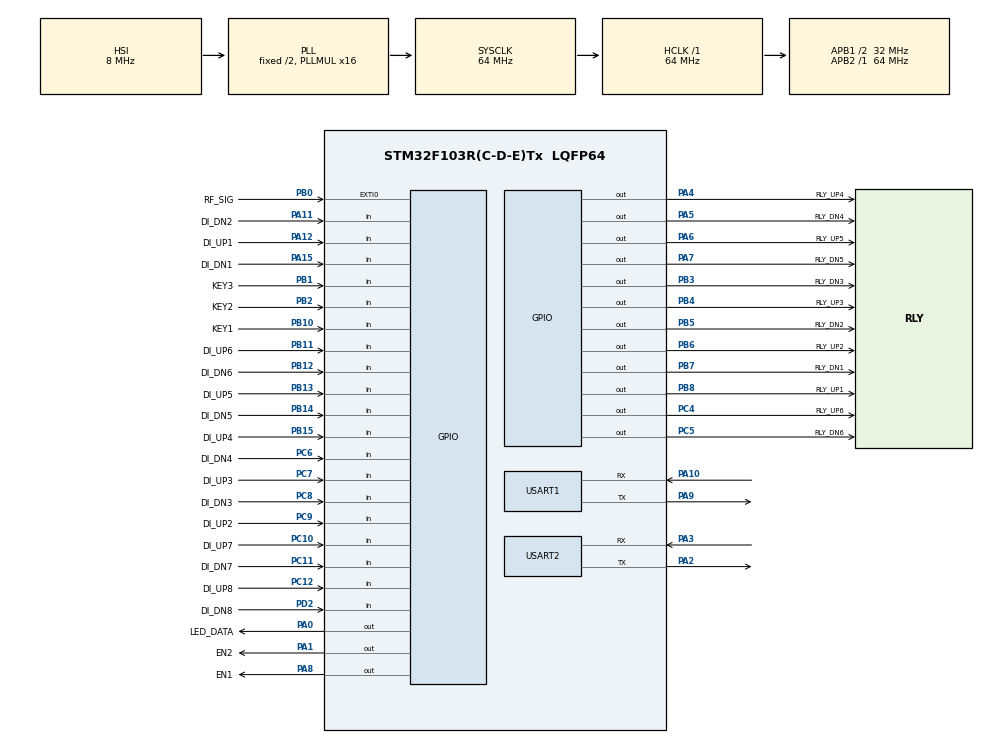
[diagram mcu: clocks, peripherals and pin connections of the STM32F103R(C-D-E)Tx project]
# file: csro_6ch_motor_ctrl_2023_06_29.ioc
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Dma.Request0=USART1_RX
Dma.Request1=USART1_TX
Dma.Request2=USART2_RX
Dma.Request3=USART2_TX
Dma.Request4=TIM2_UP
Dma.TIM2_UP.4.Direction=DMA_MEMORY_TO_PERIPH
Dma.TIM2_UP.4.Instance=DMA1_Channel2
Dma.TIM2_UP.4.MemDataAlignment=DMA_MDATAALIGN_WORD
Dma.TIM2_UP.4.MemInc=DMA_MINC_ENABLE
Dma.TIM2_UP.4.Mode=DMA_NORMAL
Dma.TIM2_UP.4.PeriphDataAlignment=DMA_PDATAALIGN_WORD
Dma.TIM2_UP.4.PeriphInc=DMA_PINC_DISABLE
Dma.TIM2_UP.4.Priority=DMA_PRIORITY_LOW
Dma.USART1_RX.0.Direction=DMA_PERIPH_TO_MEMORY
Dma.USART1_RX.0.Instance=DMA1_Channel5
Dma.USART1_RX.0.MemDataAlignment=DMA_MDATAALIGN_BYTE
Dma.USART1_RX.0.MemInc=DMA_MINC_ENABLE
Dma.USART1_RX.0.Mode=DMA_CIRCULAR
Dma.USART1_RX.0.PeriphDataAlignment=DMA_PDATAALIGN_BYTE
Dma.USART1_RX.0.PeriphInc=DMA_PINC_DISABLE
Dma.USART1_RX.0.Priority=DMA_PRIORITY_LOW
Dma.USART1_TX.1.Direction=DMA_MEMORY_TO_PERIPH
Dma.USART1_TX.1.Instance=DMA1_Channel4
Dma.USART1_TX.1.MemDataAlignment=DMA_MDATAALIGN_BYTE
Dma.USART1_TX.1.MemInc=DMA_MINC_ENABLE
Dma.USART1_TX.1.Mode=DMA_NORMAL
Dma.USART1_TX.1.PeriphDataAlignment=DMA_PDATAALIGN_BYTE
Dma.USART1_TX.1.PeriphInc=DMA_PINC_DISABLE
Dma.USART1_TX.1.Priority=DMA_PRIORITY_LOW
Dma.USART2_RX.2.Direction=DMA_PERIPH_TO_MEMORY
Dma.USART2_RX.2.Instance=DMA1_Channel6
Dma.USART2_RX.2.MemDataAlignment=DMA_MDATAALIGN_BYTE
Dma.USART2_RX.2.MemInc=DMA_MINC_ENABLE
Dma.USART2_RX.2.Mode=DMA_CIRCULAR
Dma.USART2_RX.2.PeriphDataAlignment=DMA_PDATAALIGN_BYTE
Dma.USART2_RX.2.PeriphInc=DMA_PINC_DISABLE
Dma.USART2_RX.2.Priority=DMA_PRIORITY_LOW
Dma.USART2_TX.3.Direction=DMA_MEMORY_TO_PERIPH
Dma.USART2_TX.3.Instance=DMA1_Channel7
Dma.USART2_TX.3.MemDataAlignment=DMA_MDATAALIGN_BYTE
Dma.USART2_TX.3.MemInc=DMA_MINC_ENABLE
Dma.USART2_TX.3.Mode=DMA_NORMAL
Dma.USART2_TX.3.PeriphDataAlignment=DMA_PDATAALIGN_BYTE
Dma.USART2_TX.3.PeriphInc=DMA_PINC_DISABLE
Dma.USART2_TX.3.Priority=DMA_PRIORITY_LOW
FREERTOS.Tasks01=Task01,47,128,StartTask01,Default,NULL,Dynamic,NULL,NULL;Task02,45,128,StartTask02,Default,NULL,Dynamic,NULL,NULL;Task03,43,128,StartTask03,Default,NULL,Dynamic,NULL,NULL;Task04,41,128,StartTask04,Default,NULL,Dynamic,NULL,NULL;Task05,24,128,StartTask05,Default,NULL,Dynamic,NULL,NULL
FREERTOS.configTOTAL_HEAP_SIZE=4096
FREERTOS.configUSE_NEWLIB_REENTRANT=1
Mcu.Family=STM32F1
Mcu.Name=STM32F103R(C-D-E)Tx
Mcu.Package=LQFP64
NVIC.DMA1_Channel2_IRQn=true\:5\:0\:false\:false\:true\:true\:false\:true\:true
NVIC.DMA1_Channel4_IRQn=true\:5\:0\:false\:false\:true\:true\:false\:true\:true
NVIC.DMA1_Channel5_IRQn=true\:5\:0\:false\:false\:true\:true\:false\:true\:true
NVIC.DMA1_Channel6_IRQn=true\:5\:0\:false\:false\:true\:true\:false\:true\:true
NVIC.DMA1_Channel7_IRQn=true\:5\:0\:false\:false\:true\:true\:false\:true\:true
NVIC.EXTI0_IRQn=true\:5\:0\:false\:false\:true\:true\:true\:true\:true
NVIC.PriorityGroup=NVIC_PRIORITYGROUP_4
NVIC.TIM2_IRQn=true\:5\:0\:false\:false\:true\:true\:true\:true\:true
NVIC.TIM3_IRQn=true\:5\:0\:false\:false\:true\:true\:true\:true\:true
NVIC.TIM8_UP_IRQn=true\:15\:0\:false\:false\:true\:false\:false\:true\:true
NVIC.TimeBase=TIM8_UP_IRQn
NVIC.TimeBaseIP=TIM8
NVIC.USART1_IRQn=true\:5\:0\:false\:false\:true\:true\:true\:true\:true
NVIC.USART2_IRQn=true\:5\:0\:false\:false\:true\:true\:true\:true\:true
PA0-WKUP.GPIO_Label=LED_DATA
PA0-WKUP.GPIO_PuPd=GPIO_PULLDOWN
PA0-WKUP.GPIO_Speed=GPIO_SPEED_FREQ_HIGH
PA0-WKUP.PinState=GPIO_PIN_RESET
PA0-WKUP.Signal=GPIO_Output
PA1.GPIO_Label=EN2
PA1.GPIO_PuPd=GPIO_PULLDOWN
PA1.Signal=GPIO_Output
PA10.Mode=Asynchronous
PA10.Signal=USART1_RX
PA11.GPIO_Label=DI_DN2
PA11.GPIO_PuPd=GPIO_PULLDOWN
PA11.Signal=GPIO_Input
PA12.GPIO_Label=DI_UP1
PA12.GPIO_PuPd=GPIO_PULLDOWN
PA12.Signal=GPIO_Input
PA13.GPIO_Label=SWDIO
PA13.Mode=Serial_Wire
PA13.Signal=SYS_JTMS-SWDIO
PA14.GPIO_Label=SWCLK
PA14.Mode=Serial_Wire
PA14.Signal=SYS_JTCK-SWCLK
PA15.GPIO_Label=DI_DN1
PA15.GPIO_PuPd=GPIO_PULLDOWN
PA15.Signal=GPIO_Input
PA2.Mode=Asynchronous
PA2.Signal=USART2_TX
PA3.Mode=Asynchronous
PA3.Signal=USART2_RX
PA4.GPIO_Label=RLY_UP4
PA4.GPIO_PuPd=GPIO_PULLDOWN
PA4.Signal=GPIO_Output
PA5.GPIO_Label=RLY_DN4
PA5.GPIO_PuPd=GPIO_PULLDOWN
PA5.Signal=GPIO_Output
PA6.GPIO_Label=RLY_UP5
PA6.GPIO_PuPd=GPIO_PULLDOWN
PA6.Signal=GPIO_Output
PA7.GPIO_Label=RLY_DN5
PA7.GPIO_PuPd=GPIO_PULLDOWN
PA7.Signal=GPIO_Output
PA8.GPIO_Label=EN1
PA8.GPIO_PuPd=GPIO_PULLDOWN
PA8.Signal=GPIO_Output
PA9.Mode=Asynchronous
PA9.Signal=USART1_TX
PB0.GPIO_Label=RF_SIG
PB0.Signal=GPXTI0
PB1.GPIO_Label=KEY3
PB1.GPIO_PuPd=GPIO_PULLDOWN
PB1.Signal=GPIO_Input
PB10.GPIO_Label=KEY1
PB10.GPIO_PuPd=GPIO_PULLDOWN
PB10.Signal=GPIO_Input
PB11.GPIO_Label=DI_UP6
PB11.GPIO_PuPd=GPIO_PULLDOWN
PB11.Signal=GPIO_Input
PB12.GPIO_Label=DI_DN6
PB12.GPIO_PuPd=GPIO_PULLDOWN
PB12.Signal=GPIO_Input
PB13.GPIO_Label=DI_UP5
PB13.GPIO_PuPd=GPIO_PULLDOWN
PB13.Signal=GPIO_Input
PB14.GPIO_Label=DI_DN5
PB14.GPIO_PuPd=GPIO_PULLDOWN
PB14.Signal=GPIO_Input
PB15.GPIO_Label=DI_UP4
PB15.GPIO_PuPd=GPIO_PULLDOWN
PB15.Signal=GPIO_Input
PB2.GPIO_Label=KEY2
PB2.GPIO_PuPd=GPIO_PULLDOWN
PB2.Signal=GPIO_Input
PB3.GPIO_Label=RLY_DN3
PB3.GPIO_PuPd=GPIO_PULLDOWN
PB3.Signal=GPIO_Output
PB4.GPIO_Label=RLY_UP3
PB4.GPIO_PuPd=GPIO_PULLDOWN
PB4.Signal=GPIO_Output
PB5.GPIO_Label=RLY_DN2
PB5.GPIO_PuPd=GPIO_PULLDOWN
PB5.Signal=GPIO_Output
PB6.GPIO_Label=RLY_UP2
PB6.GPIO_PuPd=GPIO_PULLDOWN
PB6.Signal=GPIO_Output
PB7.GPIO_Label=RLY_DN1
PB7.GPIO_PuPd=GPIO_PULLDOWN
PB7.Signal=GPIO_Output
PB8.GPIO_Label=RLY_UP1
PB8.GPIO_PuPd=GPIO_PULLDOWN
PB8.Signal=GPIO_Output
PC10.GPIO_Label=DI_UP7
PC10.GPIO_PuPd=GPIO_PULLDOWN
PC10.Signal=GPIO_Input
PC11.GPIO_Label=DI_DN7
PC11.GPIO_PuPd=GPIO_PULLDOWN
PC11.Signal=GPIO_Input
PC12.GPIO_Label=DI_UP8
PC12.GPIO_PuPd=GPIO_PULLDOWN
PC12.Signal=GPIO_Input
PC4.GPIO_Label=RLY_UP6
PC4.GPIO_PuPd=GPIO_PULLDOWN
PC4.Signal=GPIO_Output
PC5.GPIO_Label=RLY_DN6
PC5.GPIO_PuPd=GPIO_PULLDOWN
PC5.Signal=GPIO_Output
PC6.GPIO_Label=DI_DN4
PC6.GPIO_PuPd=GPIO_PULLDOWN
PC6.Signal=GPIO_Input
PC7.GPIO_Label=DI_UP3
PC7.GPIO_PuPd=GPIO_PULLDOWN
PC7.Signal=GPIO_Input
PC8.GPIO_Label=DI_DN3
PC8.GPIO_PuPd=GPIO_PULLDOWN
PC8.Signal=GPIO_Input
PC9.GPIO_Label=DI_UP2
PC9.GPIO_PuPd=GPIO_PULLDOWN
PC9.Signal=GPIO_Input
PD2.GPIO_Label=DI_DN8
PD2.GPIO_PuPd=GPIO_PULLDOWN
PD2.Signal=GPIO_Input
ProjectManager.HeapSize=0x800
ProjectManager.StackSize=0x800
ProjectManager.TargetToolchain=STM32CubeIDE
RCC.AHBFreq_Value=64000000
RCC.APB1CLKDivider=RCC_HCLK_DIV2
RCC.APB1Freq_Value=32000000
RCC.APB1TimFreq_Value=64000000
RCC.APB2Freq_Value=64000000
RCC.APB2TimFreq_Value=64000000
RCC.HCLKFreq_Value=64000000
RCC.PLLMUL=RCC_PLL_MUL16
RCC.SYSCLKFreq_VALUE=64000000
RCC.SYSCLKSource=RCC_SYSCLKSOURCE_PLLCLK
RCC.USBFreq_Value=64000000
TIM3.Prescaler=63
USART1.VirtualMode=VM_ASYNC
USART2.VirtualMode=VM_ASYNC
VP_FREERTOS_VS_CMSIS_V2.Mode=CMSIS_V2
VP_SYS_VS_tim8.Mode=TIM8
VP_TIM2_VS_ClockSourceINT.Mode=Internal
VP_TIM3_VS_ClockSourceINT.Mode=Internal
board=custom

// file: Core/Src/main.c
/* USER CODE BEGIN Header */
/**
  ******************************************************************************
  * @file           : main.c
  * @brief          : Main program body
  ******************************************************************************
  * @attention
  *
  * Copyright (c) 2023 STMicroelectronics.
  * All rights reserved.
  *
  * This software is licensed under terms that can be found in the LICENSE file
  * in the root directory of this software component.
  * If no LICENSE file comes with this software, it is provided AS-IS.
  *
  ******************************************************************************
  */
/* USER CODE END Header */
#include "main.h"
#include "cmsis_os.h"
#include "dma.h"
#include "tim.h"
#include "usart.h"
#include "gpio.h"

void SystemClock_Config(void);
void MX_FREERTOS_Init(void);

int main(void)
{

  /* MCU Configuration--------------------------------------------------------*/

  /* Reset of all peripherals, Initializes the Flash interface and the Systick. */
  HAL_Init();

  /* Configure the system clock */
  SystemClock_Config();

  /* Initialize all configured peripherals */
  MX_GPIO_Init();
  MX_DMA_Init();
  MX_TIM2_Init();
  MX_USART1_UART_Init();
  MX_USART2_UART_Init();
  MX_TIM3_Init();

  /* Init scheduler */
  osKernelInitialize();  /* Call init function for freertos objects (in freertos.c) */
  MX_FREERTOS_Init();

  /* Start scheduler */
  osKernelStart();
  /* We should never get here as control is now taken by the scheduler */
  /* Infinite loop */
  while (1)
  {

  }
}

void SystemClock_Config(void)
{
  RCC_OscInitTypeDef RCC_OscInitStruct = {0};
  RCC_ClkInitTypeDef RCC_ClkInitStruct = {0};

  /** Initializes the RCC Oscillators according to the specified parameters
  * in the RCC_OscInitTypeDef structure.
  */
  RCC_OscInitStruct.OscillatorType = RCC_OSCILLATORTYPE_HSI;
  RCC_OscInitStruct.HSIState = RCC_HSI_ON;
  RCC_OscInitStruct.HSICalibrationValue = RCC_HSICALIBRATION_DEFAULT;
  RCC_OscInitStruct.PLL.PLLState = RCC_PLL_ON;
  RCC_OscInitStruct.PLL.PLLSource = RCC_PLLSOURCE_HSI_DIV2;
  RCC_OscInitStruct.PLL.PLLMUL = RCC_PLL_MUL16;
  if (HAL_RCC_OscConfig(&RCC_OscInitStruct) != HAL_OK)
  {
    Error_Handler();
  }

  /** Initializes the CPU, AHB and APB buses clocks
  */
  RCC_ClkInitStruct.ClockType = RCC_CLOCKTYPE_HCLK|RCC_CLOCKTYPE_SYSCLK
                              |RCC_CLOCKTYPE_PCLK1|RCC_CLOCKTYPE_PCLK2;
  RCC_ClkInitStruct.SYSCLKSource = RCC_SYSCLKSOURCE_PLLCLK;
  RCC_ClkInitStruct.AHBCLKDivider = RCC_SYSCLK_DIV1;
  RCC_ClkInitStruct.APB1CLKDivider = RCC_HCLK_DIV2;
  RCC_ClkInitStruct.APB2CLKDivider = RCC_HCLK_DIV1;

  if (HAL_RCC_ClockConfig(&RCC_ClkInitStruct, FLASH_LATENCY_2) != HAL_OK)
  {
    Error_Handler();
  }
}

void HAL_TIM_PeriodElapsedCallback(TIM_HandleTypeDef *htim)
{
  if (htim->Instance == TIM8) {
    HAL_IncTick();
  }
}

void Error_Handler(void)
{
  __disable_irq();
  while (1)
  {
  }
}

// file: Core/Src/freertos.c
/* USER CODE BEGIN Header */
/**
 ******************************************************************************
 * File Name          : freertos.c
 * Description        : Code for freertos applications
 ******************************************************************************
 * @attention
 *
 * Copyright (c) 2023 STMicroelectronics.
 * All rights reserved.
 *
 * This software is licensed under terms that can be found in the LICENSE file
 * in the root directory of this software component.
 * If no LICENSE file comes with this software, it is provided AS-IS.
 *
 ******************************************************************************
 */
/* USER CODE END Header */

#include "FreeRTOS.h"
#include "task.h"
#include "main.h"
#include "cmsis_os.h"

/* USER CODE BEGIN Includes */
#include "fnd_com.h"
#include "fnd_input.h"
#include "fnd_output.h"
#include "fnd_led.h"
#include "ee.h"

/* USER CODE END Includes */

/* Definitions for Task01 */
osThreadId_t Task01Handle;
const osThreadAttr_t Task01_attributes = {
    .name = "Task01",
    .stack_size = 128 * 4,
    .priority = (osPriority_t)osPriorityHigh7,
};
/* Definitions for Task02 */
osThreadId_t Task02Handle;
const osThreadAttr_t Task02_attributes = {
    .name = "Task02",
    .stack_size = 128 * 4,
    .priority = (osPriority_t)osPriorityHigh5,
};
/* Definitions for Task03 */
osThreadId_t Task03Handle;
const osThreadAttr_t Task03_attributes = {
    .name = "Task03",
    .stack_size = 128 * 4,
    .priority = (osPriority_t)osPriorityHigh3,
};
/* Definitions for Task04 */
osThreadId_t Task04Handle;
const osThreadAttr_t Task04_attributes = {
    .name = "Task04",
    .stack_size = 128 * 4,
    .priority = (osPriority_t)osPriorityHigh1,
};
/* Definitions for Task05 */
osThreadId_t Task05Handle;
const osThreadAttr_t Task05_attributes = {
    .name = "Task05",
    .stack_size = 128 * 4,
    .priority = (osPriority_t)osPriorityNormal,
};

void StartTask01(void *argument);
void StartTask02(void *argument);
void StartTask03(void *argument);
void StartTask04(void *argument);
void StartTask05(void *argument);

void MX_FREERTOS_Init(void); /* (MISRA C 2004 rule 8.1) */

void MX_FREERTOS_Init(void)
{
  /* USER CODE BEGIN Init */
  fnd_com_modbus_rtu_init();
  ee_init();

  /* USER CODE END Init */

  /* Create the thread(s) */
  /* creation of Task01 */
  Task01Handle = osThreadNew(StartTask01, NULL, &Task01_attributes);

  /* creation of Task02 */
  Task02Handle = osThreadNew(StartTask02, NULL, &Task02_attributes);

  /* creation of Task03 */
  Task03Handle = osThreadNew(StartTask03, NULL, &Task03_attributes);

  /* creation of Task04 */
  Task04Handle = osThreadNew(StartTask04, NULL, &Task04_attributes);

  /* creation of Task05 */
  Task05Handle = osThreadNew(StartTask05, NULL, &Task05_attributes);

}

void StartTask01(void *argument)
{
  /* USER CODE BEGIN StartTask01 */
  /* Infinite loop */
  for (;;)
  {
    fnd_com_modbus_rtu_slave1_wait();
  }
  /* USER CODE END StartTask01 */
}

void StartTask02(void *argument)
{
  /* USER CODE BEGIN StartTask02 */
  /* Infinite loop */
  for (;;)
  {
    fnd_com_modbus_rtu_slave2_wait();
  }
  /* USER CODE END StartTask02 */
}

void StartTask03(void *argument)
{
  /* USER CODE BEGIN StartTask03 */
  /* Infinite loop */
  for (;;)
  {
    fnd_input_update_value();
    fnd_output_update_value();
    osDelay(10);
  }
  /* USER CODE END StartTask03 */
}

void StartTask04(void *argument)
{
  for (;;)
  {
    osDelay(1);
  }
}

void StartTask05(void *argument)
{
  /* USER CODE BEGIN StartTask05 */
  /* Infinite loop */
  for (;;)
  {
    fnd_led_update();
    osDelay(10);
  }
  /* USER CODE END StartTask05 */
}
